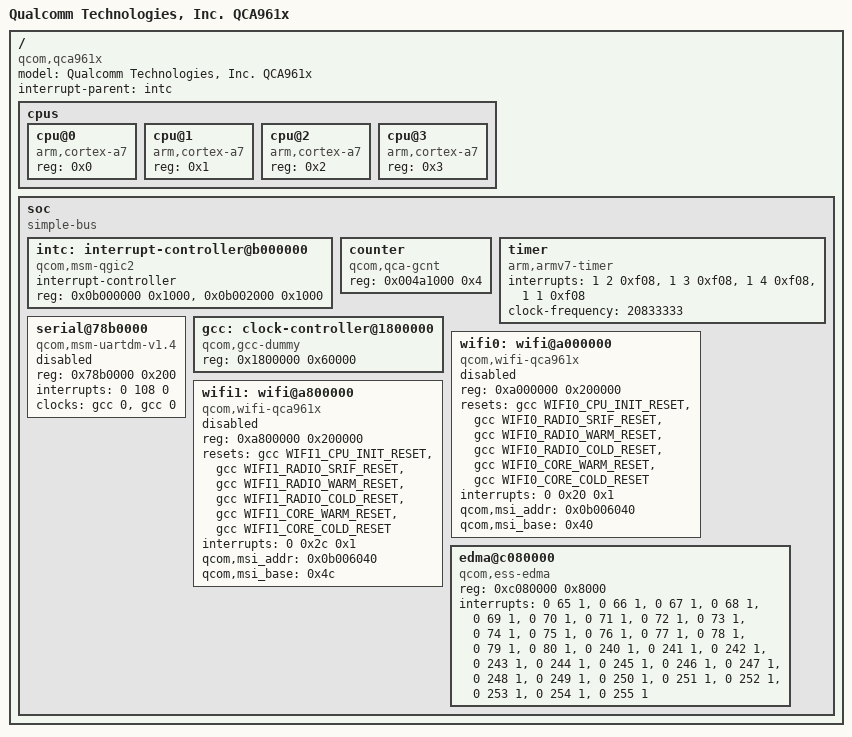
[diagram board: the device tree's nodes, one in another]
/*
 * Copyright (c) 2014, The Linux Foundation. All rights reserved.
 *
 * This program is free software; you can redistribute it and/or modify
 * it under the terms of the GNU General Public License version 2 and
 * only version 2 as published by the Free Software Foundation.
 *
 * This program is distributed in the hope that it will be useful,
 * but WITHOUT ANY WARRANTY; without even the implied warranty of
 * MERCHANTABILITY or FITNESS FOR A PARTICULAR PURPOSE.  See the
 * GNU General Public License for more details.
 */

/dts-v1/;

#include "skeleton.dtsi"
#include <dt-bindings/reset/qcom,gcc-qca961x.h>
#include <dt-bindings/clock/qcom,gcc-dummy.h>

/ {
	model = "Qualcomm Technologies, Inc. QCA961x";
	compatible = "qcom,qca961x";
	interrupt-parent = <&intc>;

	cpus {
		#address-cells = <1>;
		#size-cells = <0>;
		cpu@0 {
			device_type = "cpu";
			compatible = "arm,cortex-a7";
			reg = <0x0>;
		};

		cpu@1 {
			device_type = "cpu";
			compatible = "arm,cortex-a7";
			reg = <0x1>;
		};

		cpu@2 {
			device_type = "cpu";
			compatible = "arm,cortex-a7";
			reg = <0x2>;
		};

		cpu@3 {
			device_type = "cpu";
			compatible = "arm,cortex-a7";
			reg = <0x3>;
		};
	};

	soc {
		#address-cells = <1>;
		#size-cells = <1>;
		ranges;
		compatible = "simple-bus";

		intc: interrupt-controller@b000000 {
			compatible = "qcom,msm-qgic2";
			interrupt-controller;
			#interrupt-cells = <3>;
			reg = <0x0b000000 0x1000>,
			<0x0b002000 0x1000>;
		};

		counter {
			compatible = "qcom,qca-gcnt";
			reg = <0x004a1000 0x4>;
		};

		timer {
			compatible = "arm,armv7-timer";
			interrupts = <1 2 0xf08>,
				     <1 3 0xf08>,
				     <1 4 0xf08>,
				     <1 1 0xf08>;
			clock-frequency = <20833333>;
		};

		serial@78b0000 {
			compatible = "qcom,msm-uartdm-v1.4", "qcom,msm-uartdm";
			reg = <0x78b0000 0x200>;
			interrupts = <0 108 0>;
			status = "disabled";
			clocks = <&gcc 0>,
				<&gcc 0>;
			clock-names = "core", "iface";
		};

		gcc: clock-controller@1800000 {
			compatible = "qcom,gcc-dummy";
			#clock-cells = <1>;
			#reset-cells = <1>;
			reg = <0x1800000 0x60000>;
		};

		wifi0: wifi@a000000 {
			compatible = "qcom,wifi-qca961x";
			reg = <0xa000000 0x200000>;
			resets = <&gcc WIFI0_CPU_INIT_RESET>,
				<&gcc WIFI0_RADIO_SRIF_RESET>,
				<&gcc WIFI0_RADIO_WARM_RESET>,
				<&gcc WIFI0_RADIO_COLD_RESET>,
				<&gcc WIFI0_CORE_WARM_RESET>,
				<&gcc WIFI0_CORE_COLD_RESET>;
			reset-names = "wifi_cpu_init",
				"wifi_radio_srif",
				"wifi_radio_warm",
				"wifi_radio_cold",
				"wifi_core_warm",
				"wifi_core_cold";
			/* TBD: Check if 'clocks' entry is required here - if required, add the entries once they are defined in GCC driver */
			interrupts = <0 0x20 0x1>;
			status = "disabled";
			qcom,msi_addr = <0x0b006040>;
			qcom,msi_base = <0x40>;
		};

		wifi1: wifi@a800000 {
			compatible = "qcom,wifi-qca961x";
			reg = <0xa800000 0x200000>;
			resets = <&gcc WIFI1_CPU_INIT_RESET>,
				<&gcc WIFI1_RADIO_SRIF_RESET>,
				<&gcc WIFI1_RADIO_WARM_RESET>,
				<&gcc WIFI1_RADIO_COLD_RESET>,
				<&gcc WIFI1_CORE_WARM_RESET>,
				<&gcc WIFI1_CORE_COLD_RESET>;
			reset-names = "wifi_cpu_init",
				"wifi_radio_srif",
				"wifi_radio_warm",
				"wifi_radio_cold",
				"wifi_core_warm",
				"wifi_core_cold";
			/* TBD: Check if 'clocks' entry is required here - if required, add the entries once they are defined in GCC driver */
			interrupts = <0 0x2c 0x1>;
			status = "disabled";
			qcom,msi_addr = <0x0b006040>;
			qcom,msi_base = <0x4c>;
		};

		edma@c080000 {
			compatible = "qcom,ess-edma";
			reg = <0xc080000 0x8000>;
			interrupts = <0 65 1>,
					<0 66 1>,
					<0 67 1>,
					<0 68 1>,
					<0 69 1>,
					<0 70 1>,
					<0 71 1>,
					<0 72 1>,
					<0 73 1>,
					<0 74 1>,
					<0 75 1>,
					<0 76 1>,
					<0 77 1>,
					<0 78 1>,
					<0 79 1>,
					<0 80 1>,
					<0 240 1>,
					<0 241 1>,
					<0 242 1>,
					<0 243 1>,
					<0 244 1>,
					<0 245 1>,
					<0 246 1>,
					<0 247 1>,
					<0 248 1>,
					<0 249 1>,
					<0 250 1>,
					<0 251 1>,
					<0 252 1>,
					<0 253 1>,
					<0 254 1>,
					<0 255 1>;
		};
	};
};
